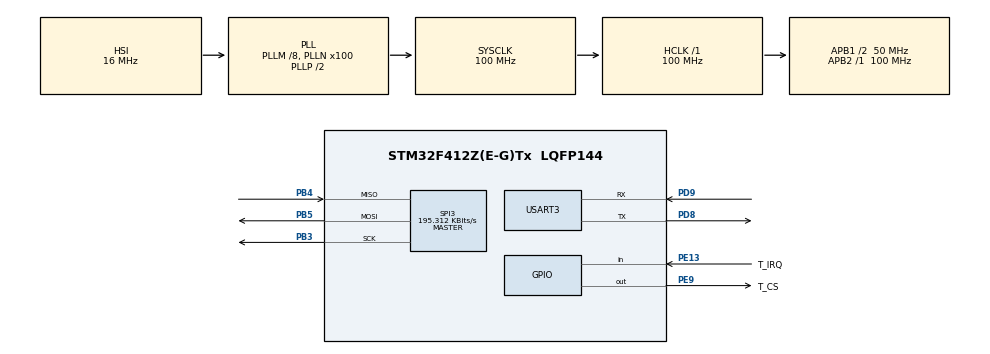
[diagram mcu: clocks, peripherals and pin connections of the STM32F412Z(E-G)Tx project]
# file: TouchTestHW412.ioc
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Mcu.Family=STM32F4
Mcu.Name=STM32F412Z(E-G)Tx
Mcu.Package=LQFP144
NVIC.PriorityGroup=NVIC_PRIORITYGROUP_4
PB3.Mode=Full_Duplex_Master
PB3.Signal=SPI3_SCK
PB4.Mode=Full_Duplex_Master
PB4.Signal=SPI3_MISO
PB5.Mode=Full_Duplex_Master
PB5.Signal=SPI3_MOSI
PD8.Mode=Asynchronous
PD8.Signal=USART3_TX
PD9.Mode=Asynchronous
PD9.Signal=USART3_RX
PE13.GPIO_Label=T_IRQ
PE13.Signal=GPIO_Input
PE9.GPIO_Label=T_CS
PE9.GPIO_Speed=GPIO_SPEED_FREQ_VERY_HIGH
PE9.PinState=GPIO_PIN_SET
PE9.Signal=GPIO_Output
ProjectManager.HeapSize=0x200
ProjectManager.StackSize=0x400
ProjectManager.TargetToolchain=STM32CubeIDE
RCC.AHBFreq_Value=100000000
RCC.APB1CLKDivider=RCC_HCLK_DIV2
RCC.APB1Freq_Value=50000000
RCC.APB1TimFreq_Value=100000000
RCC.APB2Freq_Value=100000000
RCC.APB2TimFreq_Value=100000000
RCC.CortexFreq_Value=100000000
RCC.HCLKFreq_Value=100000000
RCC.PLLM=8
RCC.PLLN=100
RCC.SYSCLKFreq_VALUE=100000000
RCC.SYSCLKSource=RCC_SYSCLKSOURCE_PLLCLK
RCC.USBFreq_Value=100000000
RCC.VCOOutputFreq_Value=200000000
SPI3.BaudRatePrescaler=SPI_BAUDRATEPRESCALER_256
SPI3.CalculateBaudRate=195.312 KBits/s
SPI3.Direction=SPI_DIRECTION_2LINES
SPI3.Mode=SPI_MODE_MASTER
SPI3.VirtualType=VM_MASTER
USART3.VirtualMode=VM_ASYNC
board=custom

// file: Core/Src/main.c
/* USER CODE BEGIN Header */
/**
  ******************************************************************************
  * @file           : main.c
  * @brief          : Main program body
  ******************************************************************************
  * @attention
  *
  * <h2><center>&copy; Copyright (c) 2020 STMicroelectronics.
  * All rights reserved.</center></h2>
  *
  * This software component is licensed by ST under BSD 3-Clause license,
  * the "License"; You may not use this file except in compliance with the
  * License. You may obtain a copy of the License at:
  *                        opensource.org/licenses/BSD-3-Clause
  *
  ******************************************************************************
  */
/* USER CODE END Header */

#include "main.h"

/* USER CODE BEGIN Includes */
#include <stdio.h>
#include <string.h>
#include "xpt2046.h"

/* USER CODE END Includes */

SPI_HandleTypeDef hspi3;

UART_HandleTypeDef huart3;

void SystemClock_Config(void);
static void MX_GPIO_Init(void);
static void MX_SPI3_Init(void);
static void MX_USART3_UART_Init(void);

int main(void)
{
  /* USER CODE BEGIN 1 */
	uint16_t x, y;
	uint8_t str[16];
  /* USER CODE END 1 */

  /* MCU Configuration--------------------------------------------------------*/

  /* Reset of all peripherals, Initializes the Flash interface and the Systick. */
  HAL_Init();

  /* Configure the system clock */
  SystemClock_Config();

  /* Initialize all configured peripherals */
  MX_GPIO_Init();
  MX_SPI3_Init();
  MX_USART3_UART_Init();
  /* USER CODE BEGIN 2 */
  __HAL_SPI_DISABLE(&hspi3);
  x = y = 0;
  /* USER CODE END 2 */

  /* Infinite loop */
  while (1)
  {

    /* USER CODE BEGIN 3 */
	  XPT2046_Update(&x, &y);
	  if (XPT2046_IsReasonable(x, y)) {
		  sprintf((char *)str, "%d %d\n", x, y);
		  HAL_UART_Transmit(&huart3, str, strlen((char *)str), 1000);
	  }
	  HAL_Delay(200);
  }
  /* USER CODE END 3 */
}

void SystemClock_Config(void)
{
  RCC_OscInitTypeDef RCC_OscInitStruct = {0};
  RCC_ClkInitTypeDef RCC_ClkInitStruct = {0};

  /** Configure the main internal regulator output voltage
  */
  __HAL_RCC_PWR_CLK_ENABLE();
  __HAL_PWR_VOLTAGESCALING_CONFIG(PWR_REGULATOR_VOLTAGE_SCALE1);
  /** Initializes the CPU, AHB and APB busses clocks
  */
  RCC_OscInitStruct.OscillatorType = RCC_OSCILLATORTYPE_HSI;
  RCC_OscInitStruct.HSIState = RCC_HSI_ON;
  RCC_OscInitStruct.HSICalibrationValue = RCC_HSICALIBRATION_DEFAULT;
  RCC_OscInitStruct.PLL.PLLState = RCC_PLL_ON;
  RCC_OscInitStruct.PLL.PLLSource = RCC_PLLSOURCE_HSI;
  RCC_OscInitStruct.PLL.PLLM = 8;
  RCC_OscInitStruct.PLL.PLLN = 100;
  RCC_OscInitStruct.PLL.PLLP = RCC_PLLP_DIV2;
  RCC_OscInitStruct.PLL.PLLQ = 2;
  RCC_OscInitStruct.PLL.PLLR = 2;
  if (HAL_RCC_OscConfig(&RCC_OscInitStruct) != HAL_OK)
  {
    Error_Handler();
  }
  /** Initializes the CPU, AHB and APB busses clocks
  */
  RCC_ClkInitStruct.ClockType = RCC_CLOCKTYPE_HCLK|RCC_CLOCKTYPE_SYSCLK
                              |RCC_CLOCKTYPE_PCLK1|RCC_CLOCKTYPE_PCLK2;
  RCC_ClkInitStruct.SYSCLKSource = RCC_SYSCLKSOURCE_PLLCLK;
  RCC_ClkInitStruct.AHBCLKDivider = RCC_SYSCLK_DIV1;
  RCC_ClkInitStruct.APB1CLKDivider = RCC_HCLK_DIV2;
  RCC_ClkInitStruct.APB2CLKDivider = RCC_HCLK_DIV1;

  if (HAL_RCC_ClockConfig(&RCC_ClkInitStruct, FLASH_LATENCY_3) != HAL_OK)
  {
    Error_Handler();
  }
}

static void MX_SPI3_Init(void)
{

  /* SPI3 parameter configuration*/
  hspi3.Instance = SPI3;
  hspi3.Init.Mode = SPI_MODE_MASTER;
  hspi3.Init.Direction = SPI_DIRECTION_2LINES;
  hspi3.Init.DataSize = SPI_DATASIZE_8BIT;
  hspi3.Init.CLKPolarity = SPI_POLARITY_LOW;
  hspi3.Init.CLKPhase = SPI_PHASE_1EDGE;
  hspi3.Init.NSS = SPI_NSS_SOFT;
  hspi3.Init.BaudRatePrescaler = SPI_BAUDRATEPRESCALER_256;
  hspi3.Init.FirstBit = SPI_FIRSTBIT_MSB;
  hspi3.Init.TIMode = SPI_TIMODE_DISABLE;
  hspi3.Init.CRCCalculation = SPI_CRCCALCULATION_DISABLE;
  hspi3.Init.CRCPolynomial = 10;
  if (HAL_SPI_Init(&hspi3) != HAL_OK)
  {
    Error_Handler();
  }

}

static void MX_USART3_UART_Init(void)
{

  huart3.Instance = USART3;
  huart3.Init.BaudRate = 115200;
  huart3.Init.WordLength = UART_WORDLENGTH_8B;
  huart3.Init.StopBits = UART_STOPBITS_1;
  huart3.Init.Parity = UART_PARITY_NONE;
  huart3.Init.Mode = UART_MODE_TX_RX;
  huart3.Init.HwFlowCtl = UART_HWCONTROL_NONE;
  huart3.Init.OverSampling = UART_OVERSAMPLING_16;
  if (HAL_UART_Init(&huart3) != HAL_OK)
  {
    Error_Handler();
  }

}

static void MX_GPIO_Init(void)
{
  GPIO_InitTypeDef GPIO_InitStruct = {0};

  /* GPIO Ports Clock Enable */
  __HAL_RCC_GPIOE_CLK_ENABLE();
  __HAL_RCC_GPIOD_CLK_ENABLE();
  __HAL_RCC_GPIOB_CLK_ENABLE();

  /*Configure GPIO pin Output Level */
  HAL_GPIO_WritePin(T_CS_GPIO_Port, T_CS_Pin, GPIO_PIN_SET);

  /*Configure GPIO pin : T_CS_Pin */
  GPIO_InitStruct.Pin = T_CS_Pin;
  GPIO_InitStruct.Mode = GPIO_MODE_OUTPUT_PP;
  GPIO_InitStruct.Pull = GPIO_NOPULL;
  GPIO_InitStruct.Speed = GPIO_SPEED_FREQ_VERY_HIGH;
  HAL_GPIO_Init(T_CS_GPIO_Port, &GPIO_InitStruct);

  /*Configure GPIO pin : T_IRQ_Pin */
  GPIO_InitStruct.Pin = T_IRQ_Pin;
  GPIO_InitStruct.Mode = GPIO_MODE_INPUT;
  GPIO_InitStruct.Pull = GPIO_NOPULL;
  HAL_GPIO_Init(T_IRQ_GPIO_Port, &GPIO_InitStruct);

}

void Error_Handler(void)
{
}

/************************ (C) COPYRIGHT STMicroelectronics *****END OF FILE****/
